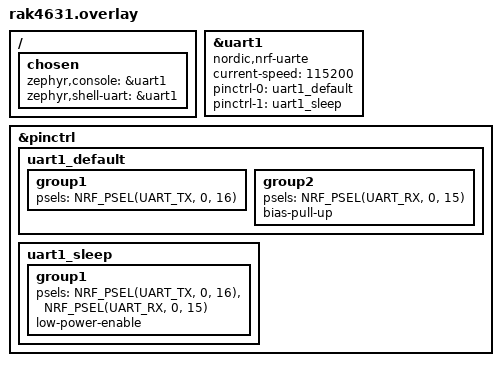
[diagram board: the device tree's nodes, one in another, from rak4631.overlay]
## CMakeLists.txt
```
cmake_minimum_required(VERSION 3.20.0)
find_package(Zephyr REQUIRED HINTS $ENV{ZEPHYR_BASE})
project(buzzer_test_node)

target_sources(app PRIVATE src/main.c)
```

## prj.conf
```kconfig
CONFIG_SERIAL=y
CONFIG_CONSOLE=y
CONFIG_UART_CONSOLE=y
CONFIG_PRINTK=y
CONFIG_GPIO=y

CONFIG_MAIN_STACK_SIZE=4096
```

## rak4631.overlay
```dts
/*
 * Buzzer test - Node (Link)
 * Console: uart1 (P0.16 TX / P0.15 RX) @ 115200 → ttyUSB0
 *
 * Buzzer 직접 GPIO:
 *   P0.17 = 12V_EN     (HIGH = 12V 부스트 ON, 부저 전원)
 *   P0.24 = BUZZER_EN  (HIGH = 부저 ON)
 *
 * 참고: link.h
 */

/ {
	chosen {
		zephyr,console = &uart1;
		zephyr,shell-uart = &uart1;
	};
};

&uart1 {
	compatible = "nordic,nrf-uarte";
	status = "okay";
	current-speed = <115200>;
	pinctrl-0 = <&uart1_default>;
	pinctrl-1 = <&uart1_sleep>;
	pinctrl-names = "default", "sleep";
};

&pinctrl {
	uart1_default: uart1_default {
		group1 {
			psels = <NRF_PSEL(UART_TX, 0, 16)>;
		};
		group2 {
			psels = <NRF_PSEL(UART_RX, 0, 15)>;
			bias-pull-up;
		};
	};

	uart1_sleep: uart1_sleep {
		group1 {
			psels = <NRF_PSEL(UART_TX, 0, 16)>,
				<NRF_PSEL(UART_RX, 0, 15)>;
			low-power-enable;
		};
	};
};
```

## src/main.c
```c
/*
 * Buzzer basic test - Node (Link)
 *
 * 동작:
 *   1. 12V_EN (P0.17) HIGH → 12V 부스트 ON
 *   2. 2초 간격으로 BUZZER_EN (P0.24) 짧게 ON (100ms beep)
 *   3. 5번 beep (총 10초) 후 BUZZER_EN / 12V_EN 모두 OFF
 *   4. 이후 idle (1초마다 상태 출력만)
 *
 * 참고: link.h
 */

#include <zephyr/kernel.h>
#include <zephyr/device.h>
#include <zephyr/drivers/gpio.h>

#define PIN_12V_EN      17  /* P0.17 */
#define PIN_BUZZER_EN   24  /* P0.24 */

#define BEEP_INTERVAL_MS  2000   /* 2초 간격 */
#define BEEP_DURATION_MS  100    /* beep 1회 길이 */
#define BEEP_COUNT        5      /* 5회 → 총 10초 */

int main(void)
{
	const struct device *gpio0;

	printk("\n========================================\n");
	printk("  Buzzer test - Node (Link)\n");
	printk("  12V_EN=P0.17  BUZZER_EN=P0.24\n");
	printk("  pattern: %d ms beep / %d ms interval / %d times\n",
	       BEEP_DURATION_MS, BEEP_INTERVAL_MS, BEEP_COUNT);
	printk("========================================\n");

	gpio0 = DEVICE_DT_GET(DT_NODELABEL(gpio0));
	if (!device_is_ready(gpio0)) {
		printk("[BUZZ] gpio0 NOT ready\n");
		return -1;
	}

	gpio_pin_configure(gpio0, PIN_12V_EN, GPIO_OUTPUT_LOW);
	gpio_pin_configure(gpio0, PIN_BUZZER_EN, GPIO_OUTPUT_LOW);

	/* 12V 부스트 ON */
	gpio_pin_set_raw(gpio0, PIN_12V_EN, 1);
	printk("[BUZZ] 12V_EN = HIGH (boost ON)\n");
	k_msleep(50);

	/* Beep 루프 */
	for (int i = 1; i <= BEEP_COUNT; i++) {
		printk("[BUZZ] beep #%d ON\n", i);
		gpio_pin_set_raw(gpio0, PIN_BUZZER_EN, 1);
		k_msleep(BEEP_DURATION_MS);

		gpio_pin_set_raw(gpio0, PIN_BUZZER_EN, 0);
		printk("[BUZZ] beep #%d OFF\n", i);

		/* 다음 beep 까지 대기 (interval - duration) */
		if (i < BEEP_COUNT) {
			k_msleep(BEEP_INTERVAL_MS - BEEP_DURATION_MS);
		}
	}

	/* 종료: 부저 + 12V 모두 OFF */
	gpio_pin_set_raw(gpio0, PIN_BUZZER_EN, 0);
	gpio_pin_set_raw(gpio0, PIN_12V_EN, 0);
	printk("\n[BUZZ] DONE — BUZZER_EN=LOW, 12V_EN=LOW\n");

	/* idle */
	uint32_t tick = 0;
	while (1) {
		k_sleep(K_SECONDS(1));
		tick++;
		printk("[BUZZ] idle tick=%u\n", tick);
	}

	return 0;
}
```
